# NAVSS0_BCDMA_0_ALIAS64K_BCDMA0_CFG_RINGRT register map
Vendor: Texas Instruments
Peripheral module from a debugger description file (folder J721S2).
Registers are 32-bit, access not given, reset 0x0 unless marked. A register's access mark holds for its fields unless they carry their own. Offsets are as the file gives them; lines under a group give offsets from that group; [hi:lo] are bit positions; {n}, {i} and the like mark numbered series; 'fields as' and 'values as' point back to an identical list; <NAME> marks a mode.

## NAVSS0_BCDMA_0_ALIAS64K_BCDMA0_CFG_RINGRT
0x10 ALIAS64K_BCDMA0__CFG__RINGRT_RT_FDB — The Ring N Doorbell Register is written by software to increment or decrement the number of entries on a Ring. One or more entries as specified by the entry_cnt field can be added to a ring with a single write operation.
  [7:0] ENTRY_CNT — Signed number of entries by which to increment the ring occupancy. For normal Tx Ring operation, this value should be a positive number. This occ value for the ring is increased by this value each time the doorbell register is written (occ absolute value will increase or decrease based on the sign of the tentry_cnt). (access NA/W)
0x18 ALIAS64K_BCDMA0__CFG__RINGRT_RT_FOCC — The Ring N Occupancy Register can be read by software to determine the total number of valid entries on a ring. The contents of each of these registers are unary ORed in order to create a pending signal for the ring which can be used for triggering hardware operations and/or for generating interrupts to the host.
  [16:0] OCC — Total number of valid entries on the ring. This value is generally intended to be incremented by doorbell pokes from software and is decremented by the DMA engine as entries are completed. (access R/NA)
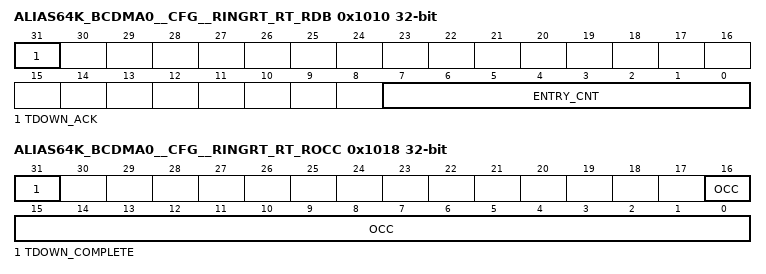
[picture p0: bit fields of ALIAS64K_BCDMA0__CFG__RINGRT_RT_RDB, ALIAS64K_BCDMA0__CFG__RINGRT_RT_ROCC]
0x1010 ALIAS64K_BCDMA0__CFG__RINGRT_RT_RDB — The Ring N Doorbell Register is written by software to increment or decrement the number of entries on a Ring. One or more entries as specified by the entry_cnt field can be added to a ring with a single write operation.
  [31] TDOWN_ACK — This bit is set to 1 to ackowledge (and clear) the tdown_complete bit in the corresponding Ring N Occupancy Register. this bit is only valid on the reverse rings (rings consumed by the Host SW) (access NA/W)
  [7:0] ENTRY_CNT — Signed number of entries by which to increment the ring occupancy. For normal Tx Ring operation, this value should be a positive number. This occ value for the ring is increased by this value each time the doorbell register is written (occ absolute value will increase or decrease based on the sign of the tentry_cnt). (access NA/W)
0x1018 ALIAS64K_BCDMA0__CFG__RINGRT_RT_ROCC — The Ring N Occupancy Register can be read by software to determine the total number of valid entries on a ring. The contents of each of these registers are unary ORed in order to create a pending signal for the ring which can be used for triggering hardware operations and/or for generating interrupts to the host.
  [31] TDOWN_COMPLETE — This bit when set indicates that a teardown is complete on the channel. This bit is cleared anytime the tdown_ack bit is written as a 1 in the corresponding Ring N Doorbell Register. This bit is only valid on the reverse rings (rings consumed by the Host SW). (access R/NA)
  [16:0] OCC — Total number of valid entries on the ring. This value is generally intended to be incremented by doorbell pokes from software and is decremented by the DMA engine as entries are completed. (access R/NA)
